# TLE984x register map
Vendor: Infineon Technologies AG; File version: 1.6
CPU: CM0 r0p0, little endian, no MPU, no FPU, 2 interrupt priority bits
Registers are 32-bit, read-write, no defined reset value unless marked. A register's access mark holds for its fields unless they carry their own. Offsets are from the block's base; [hi:lo] are bit positions; {n}, {i} and the like mark numbered series.

## CPU
Base 0xE000E000
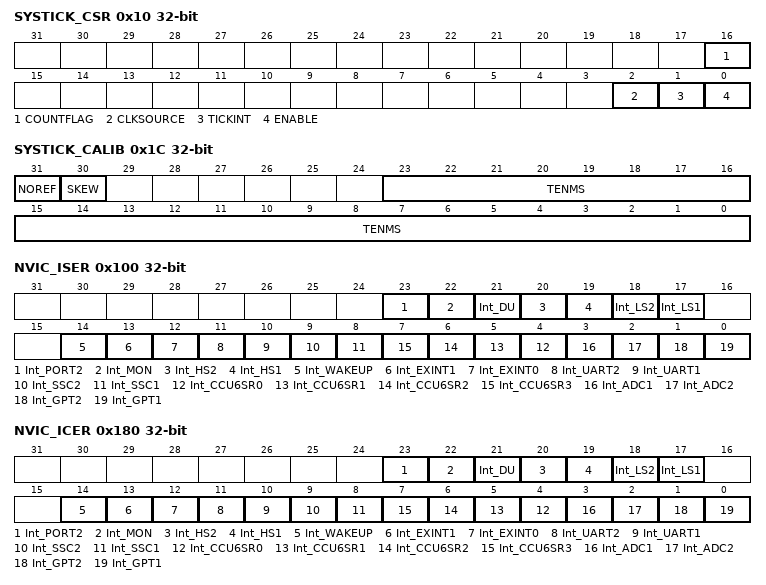
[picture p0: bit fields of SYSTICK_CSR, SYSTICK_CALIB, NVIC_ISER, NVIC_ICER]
0x10 SYSTICK_CSR access per field — SysTick Control and Status Register
  [16] COUNTFLAG ro
  [2] CLKSOURCE rw
    0=external reference clock; 1=processor clock
  [1] TICKINT rw
    0=counting down to 0 does not assert the SysTick exception request; 1=counting down to 0 asserts the SysTick exception request
  [0] ENABLE rw
    0=counter disabled; 1=counter enabled
0x14 SYSTICK_RVR — SysTick Reload Value Register
  [23:0] RELOAD
0x18 SYSTICK_CVR — SysTick Current Value Register
  [23:0] CURRENT
0x1C SYSTICK_CALIB ro — SysTick Calibration Value Register
  [31] NOREF — No Reference Clock
  [30] SKEW
  [23:0] TENMS
0x100 NVIC_ISER — Interrupt Set-Enable
  [all] fields
    0=DISABLED (no effect on write); 1=ENABLE (enables the associated interrupt)
  [23] Int_PORT2 — Interrupt Set for PORT2
  [22] Int_MON — Interrupt Set for MON
  [21] Int_DU — Interrupt Set for Differential Unit
  [20] Int_HS2 — Interrupt Set for HS2
  [19] Int_HS1 — Interrupt Set for HS1
  [18] Int_LS2 — Interrupt Set for LS2
  [17] Int_LS1 — Interrupt Set for LS1
  [14] Int_WAKEUP — Interrupt Set for WAKEUP
  [13] Int_EXINT1 — Interrupt Set for External Int 1
  [12] Int_EXINT0 — Interrupt Set for External Int 0
  [11] Int_UART2 — Interrupt Set for UART2
  [10] Int_UART1 — Interrupt Set for UART1
  [9] Int_SSC2 — Interrupt Set for SSC2
  [8] Int_SSC1 — Interrupt Set for SSC1
  [n+4] Int_CCU6SR{n} (n=0..3) — Interrupt Set for CCU6 SR{n}
  [3] Int_ADC1 — Interrupt Set for ADC1
  [2] Int_ADC2 — Interrupt Set for MU, ADC2
  [1] Int_GPT2 — Interrupt Set for GPT2
  [0] Int_GPT1 — Interrupt Set for GPT1
0x180 NVIC_ICER — Interrupt Clear-Enable
  [all] fields
    0=DISABLE (on reads the associated interrupt is disabled, no effect on write); 1=ENABLE (on reads the associated interrupt is enabled, on writes the associated interrupt is disabled)
  [23] Int_PORT2 — Interrupt Clear for PORT2
  [22] Int_MON — Interrupt Clear for MON
  [21] Int_DU — Interrupt Clear for Differential Unit
  [20] Int_HS2 — Interrupt Clear for HS2
  [19] Int_HS1 — Interrupt Clear for HS1
  [18] Int_LS2 — Interrupt Clear for LS2
  [17] Int_LS1 — Interrupt Clear for LS1
  [14] Int_WAKEUP — Interrupt Clear for WAKEUP
  [13] Int_EXINT1 — Interrupt Clear for External Int 1
  [12] Int_EXINT0 — Interrupt Clear for External Int 0
  [11] Int_UART2 — Interrupt Clear for UART2
  [10] Int_UART1 — Interrupt Clear for UART1
  [9] Int_SSC2 — Interrupt Clear for SSC2
  [8] Int_SSC1 — Interrupt Clear for SSC1
  [n+4] Int_CCU6SR{n} (n=0..3) — Interrupt Clear for CCU6 SR{n}
  [3] Int_ADC1 — Interrupt Clear for ADC1
  [2] Int_ADC2 — Interrupt Clear for MU, ADC2
  [1] Int_GPT2 — Interrupt Clear for GPT2
  [0] Int_GPT1 — Interrupt Clear for GPT1
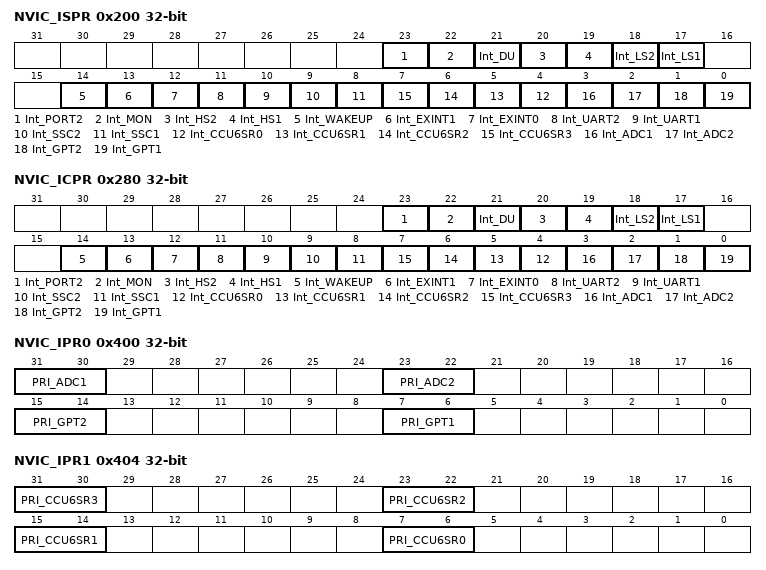
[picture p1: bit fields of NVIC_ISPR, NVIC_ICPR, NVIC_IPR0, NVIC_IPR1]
0x200 NVIC_ISPR — Interrupt Set-Pending
  [all] fields
    0=Not Pending (on reads the associated interrupt is not pending, no effect on writes); 1=Pending (the associated interrupt is pending)
  [23] Int_PORT2 — Interrupt Set Pending for PORT2
  [22] Int_MON — Interrupt Set Pending for MON
  [21] Int_DU — Interrupt Set Pending for Differential Unit
  [20] Int_HS2 — Interrupt Set Pending for HS2
  [19] Int_HS1 — Interrupt Set Pending for HS1
  [18] Int_LS2 — Interrupt Set Pending for LS2
  [17] Int_LS1 — Interrupt Set Pending for LS1
  [14] Int_WAKEUP — Interrupt Set Pending for WAKEUP
  [13] Int_EXINT1 — Interrupt Set Pending for External Int 1
  [12] Int_EXINT0 — Interrupt Set Pending for External Int 0
  [11] Int_UART2 — Interrupt Set Pending for UART2
  [10] Int_UART1 — Interrupt Set Pending for UART1
  [9] Int_SSC2 — Interrupt Set Pending for SSC2
  [8] Int_SSC1 — Interrupt Set Pending for SSC1
  [n+4] Int_CCU6SR{n} (n=0..3) — Interrupt Set Pending for CCU6 SR{n}
  [3] Int_ADC1 — Interrupt Set Pending for ADC1
  [2] Int_ADC2 — Interrupt Set Pending for MU, ADC2
  [1] Int_GPT2 — Interrupt Set Pending for GPT2
  [0] Int_GPT1 — Interrupt Set Pending for GPT1
0x280 NVIC_ICPR — Interrupt Clear-Pending
  [all] fields
    0=Not Pending (on reads the associated interrupt is not pending, no effect on writes); 1=Pending (on reads the associated interrupt is pending, on writes the status of the associated interrupt is changed to not pending)
  [23] Int_PORT2 — Interrupt Clear Pending for PORT2
  [22] Int_MON — Interrupt Clear Pending for MON
  [21] Int_DU — Interrupt Clear Pending for Differential Unit
  [20] Int_HS2 — Interrupt Clear Pending for HS2
  [19] Int_HS1 — Interrupt Clear Pending for HS1
  [18] Int_LS2 — Interrupt Clear Pending for LS2
  [17] Int_LS1 — Interrupt Clear Pending for LS1
  [14] Int_WAKEUP — Interrupt Clear Pending for WAKEUP
  [13] Int_EXINT1 — Interrupt Clear Pending for External Int 1
  [12] Int_EXINT0 — Interrupt Clear Pending for External Int 0
  [11] Int_UART2 — Interrupt Clear Pending for UART2
  [10] Int_UART1 — Interrupt Clear Pending for UART1
  [9] Int_SSC2 — Interrupt Clear Pending for SSC2
  [8] Int_SSC1 — Interrupt Clear Pending for SSC1
  [n+4] Int_CCU6SR{n} (n=0..3) — Interrupt Clear Pending for CCU6 SR{n}
  [3] Int_ADC1 — Interrupt Clear Pending for ADC1
  [2] Int_ADC2 — Interrupt Clear Pending for MU, ADC2
  [1] Int_GPT2 — Interrupt Clear Pending for GPT2
  [0] Int_GPT1 — Interrupt Clear Pending for GPT1
0x400 NVIC_IPR0 — Interrupt Priority
  [31:30] PRI_ADC1 — Priority for ADC1
  [23:22] PRI_ADC2 — Priority for MU, ADC2
  [15:14] PRI_GPT2 — Priority for GPT2
  [7:6] PRI_GPT1 — Priority for GPT1
0x404 NVIC_IPR1 — Interrupt Priority
  [8n+7:8n+6] PRI_CCU6SR{n} (n=0..3) — Priority for CCU6 SR{n}
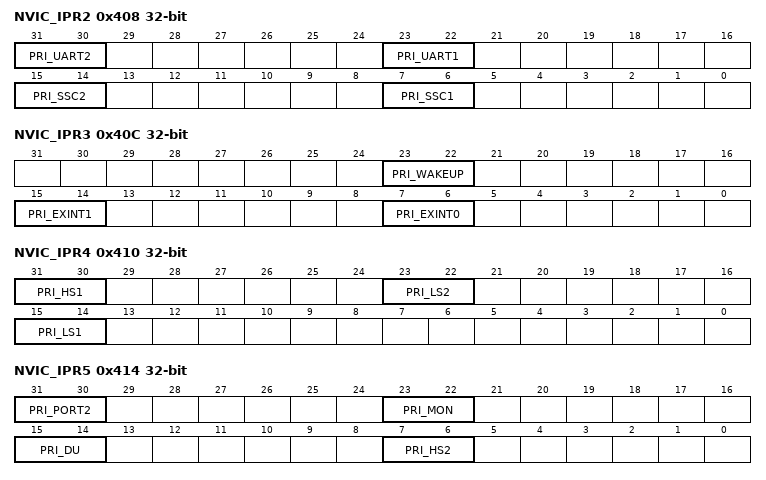
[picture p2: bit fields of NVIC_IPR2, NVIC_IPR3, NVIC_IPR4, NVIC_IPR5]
0x408 NVIC_IPR2 — Interrupt Priority
  [31:30] PRI_UART2 — Priority for CCU6 UART2
  [23:22] PRI_UART1 — Priority for CCU6 UART1
  [15:14] PRI_SSC2 — Priority for CCU6 SSC2
  [7:6] PRI_SSC1 — Priority for CCU6 SSC1
0x40C NVIC_IPR3 — Interrupt Priority
  [23:22] PRI_WAKEUP — Priority for WAKEUP
  [15:14] PRI_EXINT1 — Priority for External Int 1
  [7:6] PRI_EXINT0 — Priority for External Int 0
0x410 NVIC_IPR4 — Interrupt Priority
  [31:30] PRI_HS1 — Priority for HS1
  [23:22] PRI_LS2 — Priority for LS2
  [15:14] PRI_LS1 — Priority for LS1
0x414 NVIC_IPR5 — Interrupt Priority
  [31:30] PRI_PORT2 — Priority for PORT2
  [23:22] PRI_MON — Priority for MON
  [15:14] PRI_DU — Priority for Differential Unit
  [7:6] PRI_HS2 — Priority for HS2
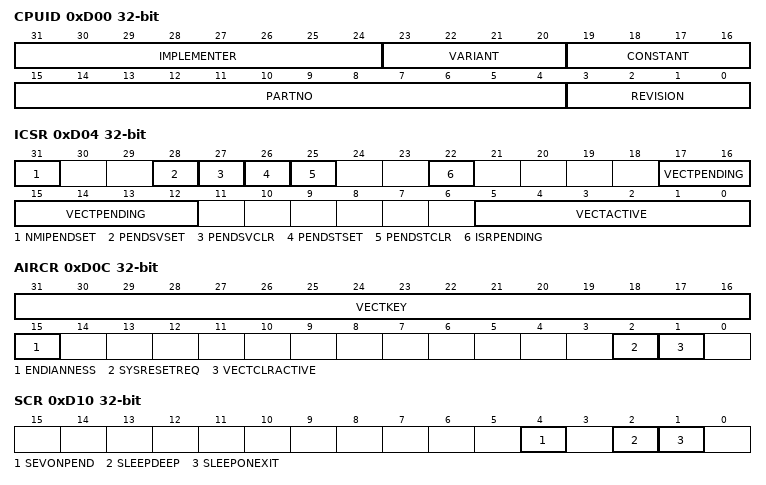
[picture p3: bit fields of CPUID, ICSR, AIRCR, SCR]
0xD00 CPUID ro — CPU ID Base Register
  [31:24] IMPLEMENTER — Implementer Code
  [23:20] VARIANT — Variant Number
  [19:16] CONSTANT
  [15:4] PARTNO — Part Number
  [3:0] REVISION — Revision Number
0xD04 ICSR access per field — Interrupt Control and State Register
  [31] NMIPENDSET rw — NMI Set Pending
    0=on writes, has no effect. On reads, NMI exception is not pending.; 1=on writes, changes the NMI exception state to pending. On reads, NMI exception is pending.
  [28] PENDSVSET rw — PENDSV Set Pending
    0=on writes, has no effect. On reads, PendSV exception is not pending.; 1=on writes, changes PendSV exception state to pending. On reads, PendSV is pending.
  [27] PENDSVCLR wo — PENDSV Clear Pending
    0=no effect; 1=remove pending state from the PENDSV exception
  [26] PENDSTSET rw — SysTick Exception Set Pending
    0=on writes, has no effect. On reads, SysTick exception is not pending.; 1=on writes, changes SysTick exception state to pending. On reads, SysTick exception is pending.
  [25] PENDSTCLR wo — SysTick Exception Clear Pending
    0=no effect; 1=removes the pending state from the SysTick exception
  [22] ISRPENDING ro — Interrupt Pending Flag
    0=interrupt not pending; 1=interrupt is pending
  [17:12] VECTPENDING ro
    0=no pending exceptions
  [5:0] VECTACTIVE ro
    0=Thread mode
0xD0C AIRCR access per field — Application Interrupt/Reset Control Register
  [31:16] VECTKEY rw — Vector Key
  [15] ENDIANNESS ro — Data Endianness
    0=little endian; 1=big endian
  [2] SYSRESETREQ wo — System Reset Request
    0=no effect; 1=request a system level reset
  [1] VECTCLRACTIVE wo
0xD10 SCR — System Control Register
  [4] SEVONPEND
    0=only enabled interrupts or events can wake-up the processor, disabled interrupts are excluded; 1=enabled events and all interrupts, including disabled interrupts, can wake-up the processor
  [2] SLEEPDEEP
    0=sleep; 1=deep sleep
  [1] SLEEPONEXIT
    0=do not sleep when returning to Thread mode; 1=enter sleep, or deep sleep, on return from an ISR to Thread mode
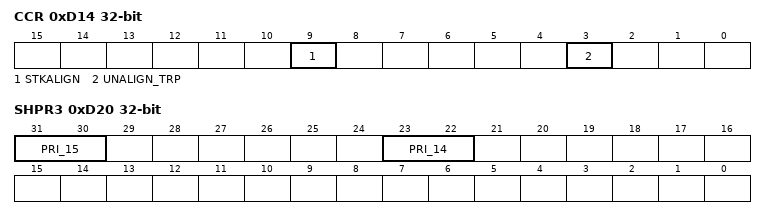
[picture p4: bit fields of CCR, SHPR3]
0xD14 CCR ro — Configuration Control Register
  [9] STKALIGN, [3] UNALIGN_TRP
0xD1C SHPR2 — System Handler Priority Register 2
  [31:30] PRI_11 — Priority of System Handler 11, SVCall
0xD20 SHPR3 — System Handler Priority Register 3
  [31:30] PRI_15 — Priority of System Handler 15, SysTick
  [23:22] PRI_14 — Priority of System Handler 14, PendSV
